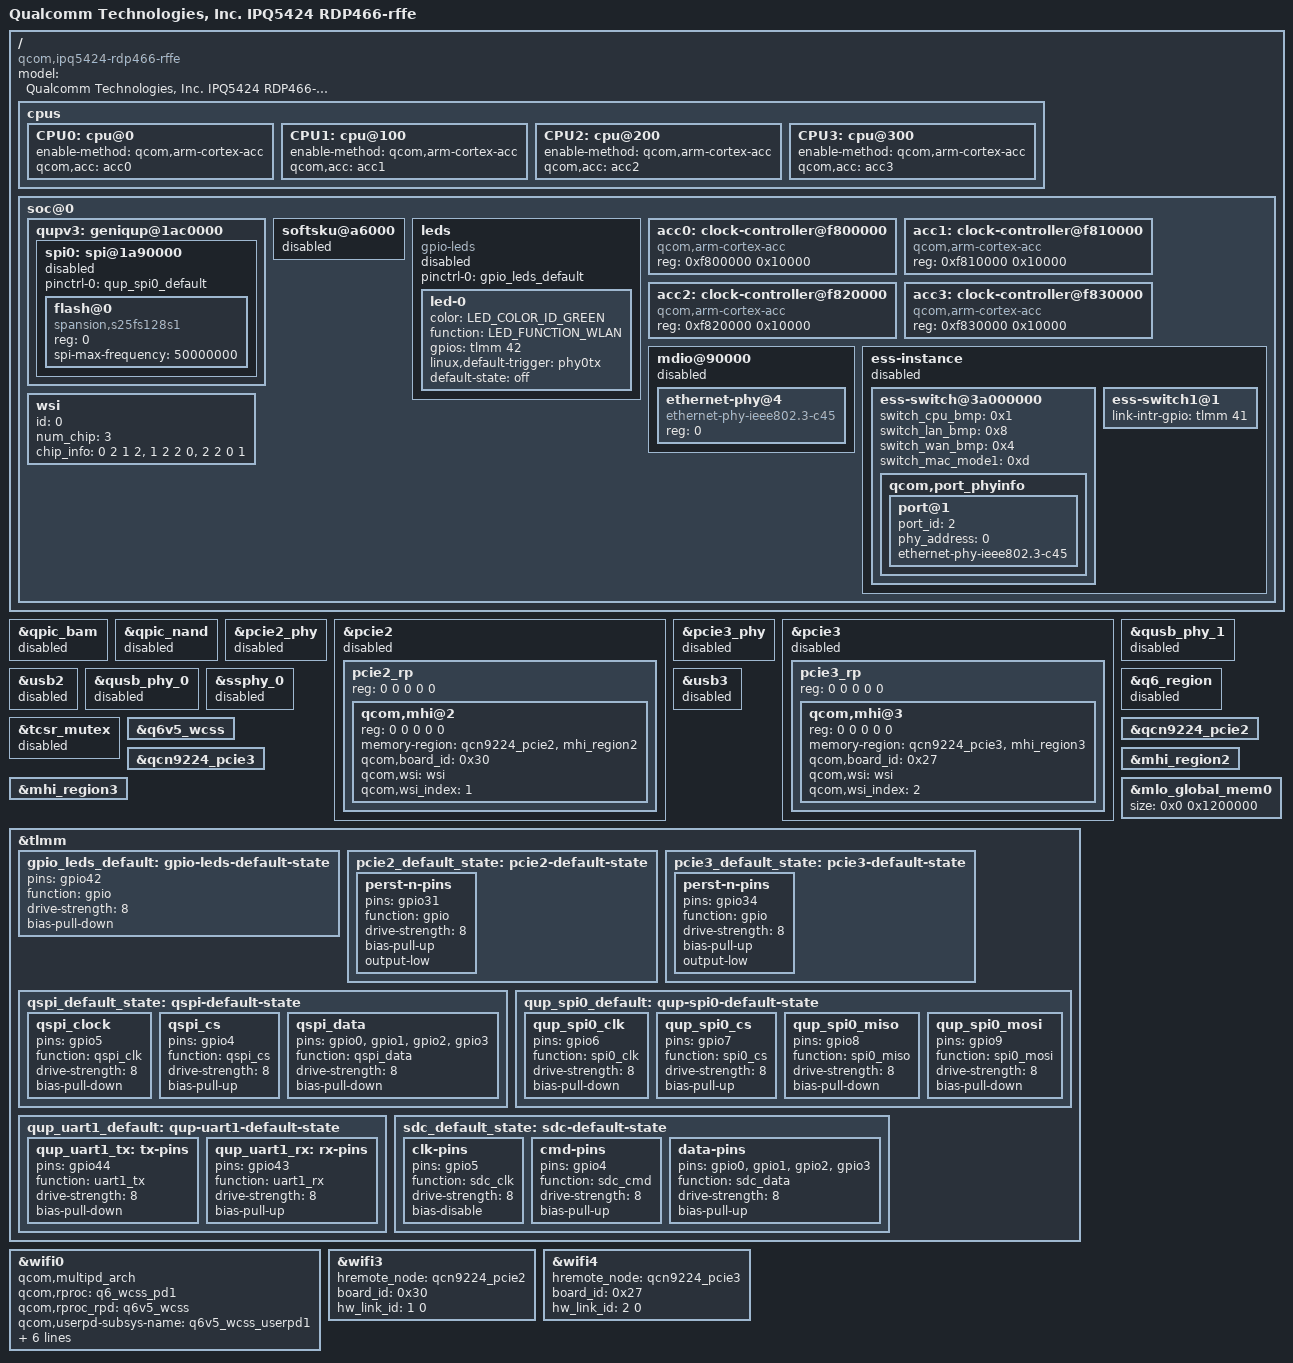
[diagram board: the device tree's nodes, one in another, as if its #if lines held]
// SPDX-License-Identifier: (GPL-2.0+ OR BSD-3-Clause)
/*
 * IPQ5424 RDP466-rffe board device tree source
 *
 * Copyright (c) 2020-2021 The Linux Foundation. All rights reserved.
 * Copyright (c) 2022-2024 Qualcomm Innovation Center, Inc. All rights reserved.
 */

/dts-v1/;

#include "ipq5424-rdp-common.dtsi"
#include "ipq5424-default-memory.dtsi"

/ {
	model = "Qualcomm Technologies, Inc. IPQ5424 RDP466-rffe";
	compatible = "qcom,ipq5424-rdp466-rffe", "qcom,ipq5424";

	/delete-node/ ctx-save;
	/delete-node/ firmware;
	/delete-node/ ipq-debug;
	/delete-node/ license_manager;
	/delete-node/ pmu;
	/delete-node/ pmu-v7;
	/delete-node/ psci;
	/delete-node/ qcom,test@0;
	/delete-node/ qti,tzlog;
	/delete-node/ wcss-smp2p;
	/delete-node/ thermal-zones;
	/delete-node/ qcn9224_legacy_irq0;
	/delete-node/ qcn9224_legacy_irq1;

	cpus: cpus {
		CPU0: cpu@0 {
			enable-method = "qcom,arm-cortex-acc";
			qcom,acc = <&acc0>;
		};

		CPU1: cpu@100 {
			enable-method = "qcom,arm-cortex-acc";
			qcom,acc = <&acc1>;
		};

		CPU2: cpu@200 {
			enable-method = "qcom,arm-cortex-acc";
			qcom,acc = <&acc2>;
		};

		CPU3: cpu@300 {
			enable-method = "qcom,arm-cortex-acc";
			qcom,acc = <&acc3>;
		};
	};

	soc@0 {
		qupv3: geniqup@1ac0000 {

			spi0: spi@1a90000 {
				pinctrl-0 = <&qup_spi0_default>;
				pinctrl-names = "default";
				status = "disabled";

				flash@0 {
					compatible = "spansion,s25fs128s1", "jedec,spi-nor";
					#address-cells = <1>;
					#size-cells = <1>;
					reg = <0>;
					spi-max-frequency = <50000000>;
				};
			};
		};

		softsku@a6000 {
			status = "disabled";
		};

		/delete-node/ efuse@a4000;
		/delete-node/ thermal-sensor@4a9000;
		/delete-node/ dp1;
		/delete-node/ dp3;
		/delete-node/ dcc@60ff000;
		/delete-node/ ess-instance;
		/delete-node/ gpio-keys;
		/delete-node/ mailbox@f400004;
		/delete-node/ mmc@7804000;
		/delete-node/ nss-ppe;
		/delete-node/ tcsr;
		/delete-node/ tmelcom;
		/delete-node/ qcom,tmelcom-qmp-client;
		/delete-node/ qmp_tmel;
		/delete-node/ etf@6047000;
		/delete-node/ etm@6480000;
		/delete-node/ etm@6580000;
		/delete-node/ etm@6680000;
		/delete-node/ etm@6780000;
		/delete-node/ edma@3ab00000;
		/delete-node/ ess-uniphy@7a00000;
		/delete-node/ funnel@6041000;
		/delete-node/ funnel@6042000;
		/delete-node/ funnel@6045000;
		/delete-node/ funnel@6781000;
		/delete-node/ mdio@90000;
		/delete-node/ nsscc@39b00000;
		/delete-node/ sram@8600000;
		/delete-node/ stm@6002000;
		/delete-node/ syscon@1937000;
		/delete-node/ system-cache-controller@800000;
		/delete-node/ qmp-tmel@32090000;
		/delete-node/ remoteproc@d100000;
		/delete-node/ rng@4c3000;
		/delete-node/ replicator@6046000;
		/delete-node/ tmc@6048000;
		/delete-node/ pcie@60000000;
		/delete-node/ pcie@70000000;
		/delete-node/ phy@84000;
		/delete-node/ phy@8c000;
		/delete-node/ watchdog@f410000;
		/delete-node/ wifi@c0000000;
		/delete-node/ wifi1@f00000;
		/delete-node/ wifi2@f00000;
		/delete-node/ userpd1;

		leds {
			compatible = "gpio-leds";
			pinctrl-0 = <&gpio_leds_default>;
			pinctrl-names = "default";
			status = "disabled";

			led-0 {
				color = <LED_COLOR_ID_GREEN>;
				function = LED_FUNCTION_WLAN;
				gpios = <&tlmm 42 GPIO_ACTIVE_HIGH>;
				linux,default-trigger = "phy0tx";
				default-state = "off";
			};
		};

		acc0: clock-controller@f800000 {
			compatible = "qcom,arm-cortex-acc";
			reg = <0xf800000 0x10000>;
		};

		acc1: clock-controller@f810000 {
			compatible = "qcom,arm-cortex-acc";
			reg = <0xf810000 0x10000>;
		};

		acc2:clock-controller@f820000 {
			compatible = "qcom,arm-cortex-acc";
			reg = <0xf820000 0x10000>;
		};

		acc3:clock-controller@f830000 {
			compatible = "qcom,arm-cortex-acc";
			reg = <0xf830000 0x10000>;
		};

		mdio@90000 {
			status = "disabled";
			ethernet-phy@4 {
				reg = <0>;
				compatible ="ethernet-phy-ieee802.3-c45";
			};
		};

		ess-instance {
			status = "disabled";
			ess-switch@3a000000 {
				switch_cpu_bmp = <0x1>;  /* cpu port bitmap */
				switch_lan_bmp = <0x8>; /* lan port bitmap */
				switch_wan_bmp = <0x4>; /* wan port bitmap */
				switch_mac_mode1 = <0xd>; /* mac mode for uniphy instance1*/

				qcom,port_phyinfo {
					port@1 {
						port_id = <2>;
						phy_address = <0>;
						ethernet-phy-ieee802.3-c45;
					};
				};
			};

			ess-switch1@1 {
				link-intr-gpio = <&tlmm 41 GPIO_ACTIVE_HIGH>;
			};
		};

		wsi: wsi {
			id = <0>;
			num_chip = <3>;
			chip_info = <0 2 1 2>,
				    <1 2 2 0>,
				    <2 2 0 1>;
			status = "okay";
		};
	};
};

&qpic_bam {
	status = "disabled";
};

&qpic_nand {
	status = "disabled";
};

&pcie2_phy {
	status = "disabled";
};

&pcie2 {
	status = "disabled";

	pcie2_rp {
		reg = <0 0 0 0 0>;

		qcom,mhi@2 {
			reg = <0 0 0 0 0>;
			memory-region = <&qcn9224_pcie2>, <&mhi_region2>;
			qcom,board_id = <0x30>;
			qcom,wsi = <&wsi>;
			qcom,wsi_index = <1>;
		};
	};
};

&pcie3_phy {
	status = "disabled";
};

&pcie3 {
	status = "disabled";

	pcie3_rp {
		reg = <0 0 0 0 0>;

		qcom,mhi@3 {
			reg = <0 0 0 0 0>;
			memory-region = <&qcn9224_pcie3>, <&mhi_region3>;
			qcom,board_id = <0x27>;
			qcom,wsi = <&wsi>;
			qcom,wsi_index = <2>;
		};
	};
};

&qusb_phy_1 {
	status = "disabled";
};

&usb2 {
	status = "disabled";
};

&qusb_phy_0 {
	status = "disabled";
};

&ssphy_0 {
	status = "disabled";
};

&usb3 {
	status = "disabled";
};

&q6_region {
	status = "disabled";
};

&tcsr_mutex {
	status = "disabled";
};

&q6v5_wcss {
	status = "okay";
};

&qcn9224_pcie2 {
	status = "okay";
};

&qcn9224_pcie3 {
	status = "okay";
};

#if defined(__MHI_BUS_RESERVED_DMA_POOL__)
&mhi_region2 {
	status = "okay";
};

&mhi_region3 {
	status = "okay";
};
#endif

&tlmm {
	gpio_leds_default: gpio-leds-default-state {
		pins = "gpio42";
		function = "gpio";
		drive-strength = <8>;
		bias-pull-down;
	};

	pcie2_default_state: pcie2-default-state {
		perst-n-pins {
			pins = "gpio31";
			function = "gpio";
			drive-strength = <8>;
			bias-pull-up;
			output-low;
		};
	};

	pcie3_default_state: pcie3-default-state {
		perst-n-pins {
			pins = "gpio34";
			function = "gpio";
			drive-strength = <8>;
			bias-pull-up;
			output-low;
		};
	};

	qspi_default_state: qspi-default-state {
		qspi_clock {
			pins = "gpio5";
			function = "qspi_clk";
			drive-strength = <8>;
			bias-pull-down;
		};

		qspi_cs {
			pins = "gpio4";
			function = "qspi_cs";
			drive-strength = <8>;
			bias-pull-up;
		};

		qspi_data {
			pins = "gpio0", "gpio1", "gpio2", "gpio3";
			function = "qspi_data";
			drive-strength = <8>;
			bias-pull-down;
		};
	};

	qup_spi0_default: qup-spi0-default-state {
		qup_spi0_clk {
			pins = "gpio6";
			function = "spi0_clk";
			drive-strength = <8>;
			bias-pull-down;
		};

		qup_spi0_cs {
			pins = "gpio7";
			function = "spi0_cs";
			drive-strength = <8>;
			bias-pull-up;
		};

		qup_spi0_miso {
			pins = "gpio8";
			function = "spi0_miso";
			drive-strength = <8>;
			bias-pull-down;
		};

		qup_spi0_mosi {
			pins = "gpio9";
			function = "spi0_mosi";
			drive-strength = <8>;
			bias-pull-down;
		};
	};

	qup_uart1_default: qup-uart1-default-state {
		qup_uart1_tx: tx-pins {
			pins = "gpio44";
			function = "uart1_tx";
			drive-strength = <8>;
			bias-pull-down;
		};

		qup_uart1_rx: rx-pins {
			pins = "gpio43";
			function = "uart1_rx";
			drive-strength = <8>;
			bias-pull-up;
		};
	};

	sdc_default_state: sdc-default-state {
		clk-pins {
			pins = "gpio5";
			function = "sdc_clk";
			drive-strength = <8>;
			bias-disable;
		};

		cmd-pins {
			pins = "gpio4";
			function = "sdc_cmd";
			drive-strength = <8>;
			bias-pull-up;
		};

		data-pins {
			pins = "gpio0", "gpio1", "gpio2", "gpio3";
			function = "sdc_data";
			drive-strength = <8>;
			bias-pull-up;
		};
	};
};

&mlo_global_mem0 {
        size = <0x0 0x1200000>;
        status = "okay";
};

&wifi0 {
	qcom,multipd_arch;
	qcom,rproc = <&q6_wcss_pd1>;
	qcom,rproc_rpd = <&q6v5_wcss>;
	qcom,userpd-subsys-name = "q6v5_wcss_userpd1";
	qcom,tgt-mem-mode = <0>;
	memory-region = <&q6_region>;
	qcom,wsi = <&wsi>;
	qcom,wsi_index = <0>;
	qcom,board_id = <0x11>;
	hw_link_id = <0 0>;
	status = "okay";
};

&wifi3 {
	hremote_node = <&qcn9224_pcie2>;
	board_id = <0x30>;
	hw_link_id = <1 0>;
	status = "okay";
};

&wifi4 {
	hremote_node = <&qcn9224_pcie3>;
	board_id = <0x27>;
	hw_link_id = <2 0>;
	status = "okay";
};
